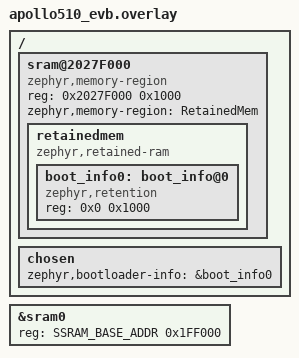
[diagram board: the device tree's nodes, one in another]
/*
 * Copyright (c) 2025, Ambiq Micro Inc. <www.ambiq.com>
 *
 * SPDX-License-Identifier: Apache-2.0
 */

/ {
		sram@2027F000 {
		compatible = "zephyr,memory-region", "mmio-sram";
		reg = <0x2027F000 0x1000>;
		zephyr,memory-region = "RetainedMem";
		status = "okay";

		retainedmem {
			compatible = "zephyr,retained-ram";
			status = "okay";
			#address-cells = <1>;
			#size-cells = <1>;

			boot_info0: boot_info@0 {
				compatible = "zephyr,retention";
				status = "okay";
				reg = <0x0 0x1000>;
			};
		};
	};

	chosen {
		zephyr,bootloader-info = &boot_info0;
	};
};


&sram0 {
	reg = <SSRAM_BASE_ADDR 0x1FF000>;
};

